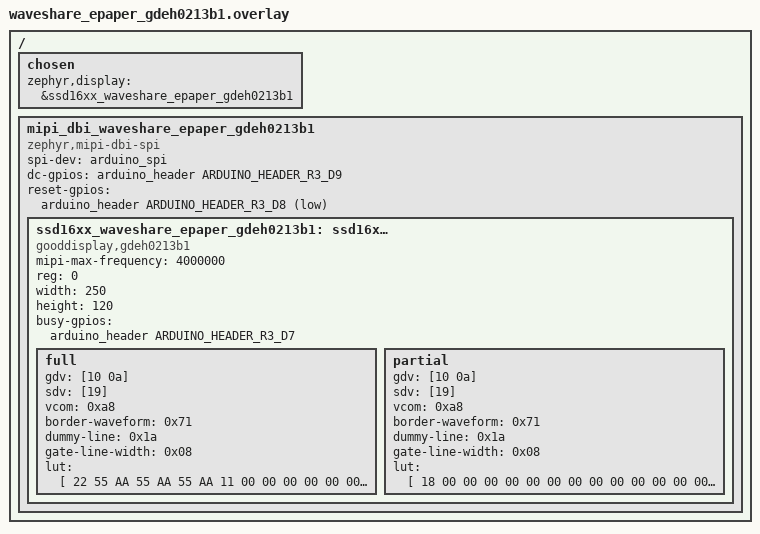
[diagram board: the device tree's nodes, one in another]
/*
 * Copyright (c) 2019, PHYTEC Messtechnik GmbH
 *
 * SPDX-License-Identifier: Apache-2.0
 */

#include "waveshare_epaper_common.dtsi"
#include <zephyr/dt-bindings/gpio/arduino-header-r3.h>

/ {
	chosen {
		zephyr,display = &ssd16xx_waveshare_epaper_gdeh0213b1;
	};

	mipi_dbi_waveshare_epaper_gdeh0213b1 {
		compatible = "zephyr,mipi-dbi-spi";
		spi-dev = <&arduino_spi>;
		dc-gpios = <&arduino_header ARDUINO_HEADER_R3_D9 GPIO_ACTIVE_HIGH>;
		reset-gpios = <&arduino_header ARDUINO_HEADER_R3_D8 GPIO_ACTIVE_LOW>;
		#address-cells = <1>;
		#size-cells = <0>;

		ssd16xx_waveshare_epaper_gdeh0213b1: ssd16xxfb@0 {
			compatible = "gooddisplay,gdeh0213b1", "solomon,ssd1673";
			mipi-max-frequency = <4000000>;
			reg = <0>;
			width = <250>;
			height = <120>;
			busy-gpios = <&arduino_header ARDUINO_HEADER_R3_D7 GPIO_ACTIVE_HIGH>;

			full {
				gdv = [10 0a];
				sdv = [19];
				vcom = <0xa8>;
				border-waveform = <0x71>;
				dummy-line = <0x1a>;
				gate-line-width = <0x08>;
				lut = [
					22 55 AA 55 AA 55 AA 11
					00 00 00 00 00 00 00 00
					1E 1E 1E 1E 1E 1E 1E 1E
					01 00 00 00 00
				];
			};

			partial {
				gdv = [10 0a];
				sdv = [19];
				vcom = <0xa8>;
				border-waveform = <0x71>;
				dummy-line = <0x1a>;
				gate-line-width = <0x08>;
				lut = [
					18 00 00 00 00 00 00 00
					00 00 00 00 00 00 00 00
					0F 01 00 00 00 00 00 00
					00 00 00 00 00
				];
			};
		};
	};
};
